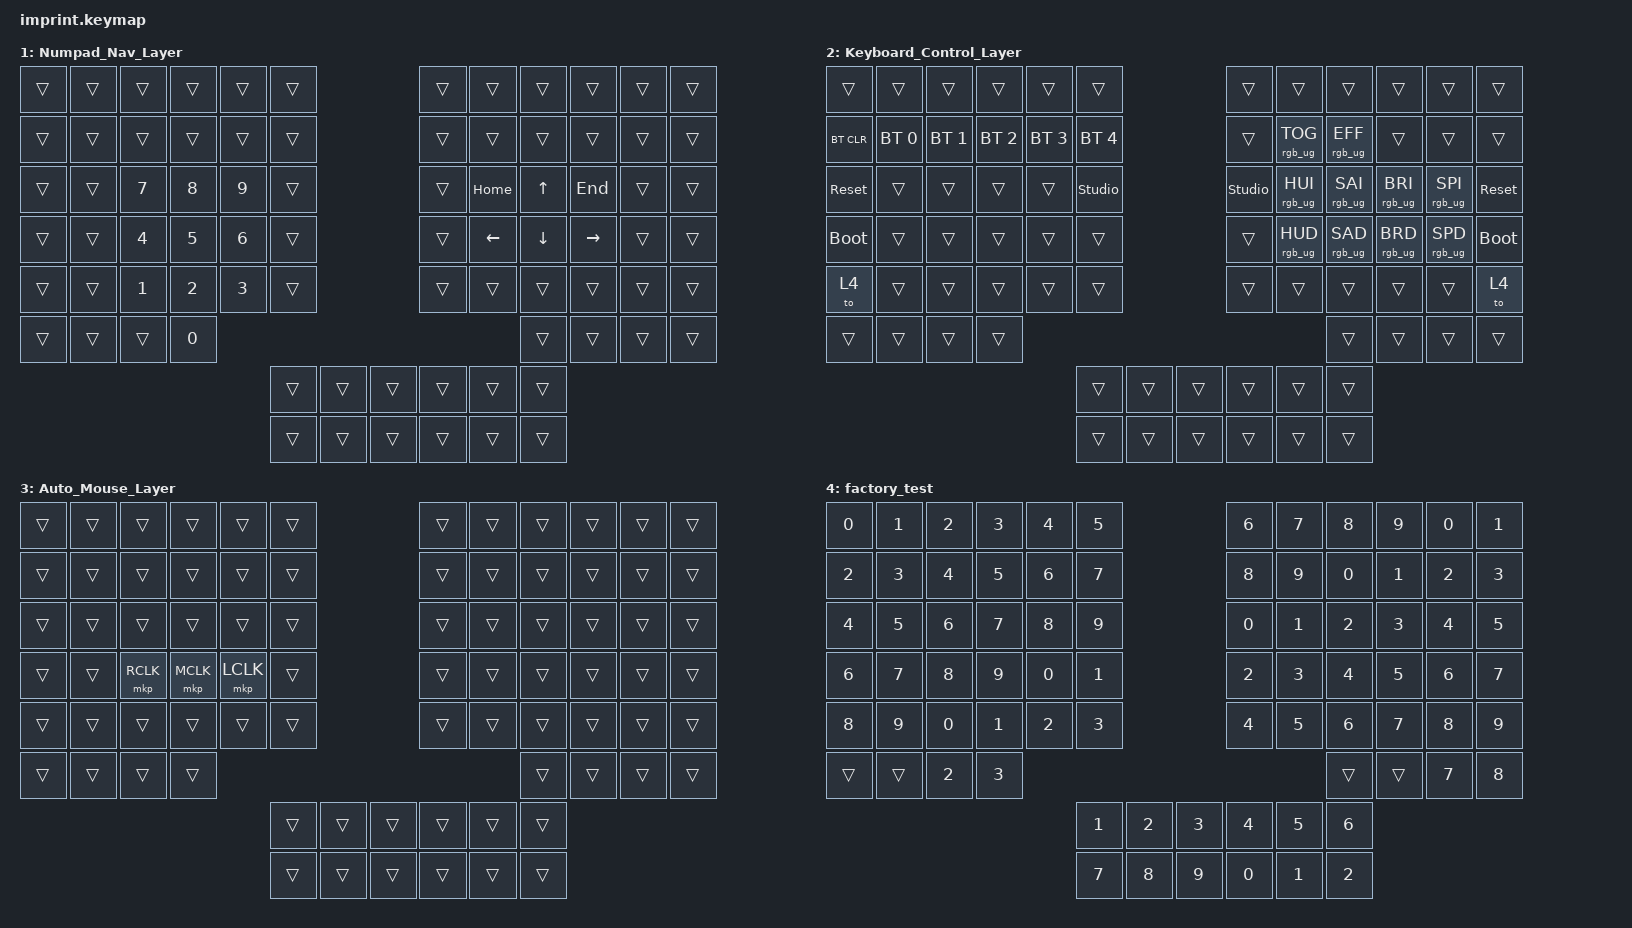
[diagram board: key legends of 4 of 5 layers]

#include <input/processors.dtsi>
#include <dt-bindings/zmk/input_transform.h>
#include <behaviors.dtsi>
#include <dt-bindings/zmk/bt.h>
#include <dt-bindings/zmk/keys.h>
#include <dt-bindings/zmk/pointing.h>
#include <dt-bindings/zmk/rgb.h>

/ {
    chosen { zmk,matrix-transform = &imprint_function_row_full_bottom_row; };
    macros {
        double_r_bkt: double_r_bkt {
            compatible = "zmk,behavior-macro";
            #binding-cells = <0>;
            bindings = <&kp LBKT &kp LBKT>;
            label = "DOUBLE_R_BKT";
        };

        double_l_bkt: double_l_bkt {
            compatible = "zmk,behavior-macro";
            #binding-cells = <0>;
            bindings = <&kp RBKT &kp RBKT>;

            label = "DOUBLE_L_BKT";
        };

        right_bfr: right_bfr {
            compatible = "zmk,behavior-macro";
            #binding-cells = <0>;
            bindings = <&kp RBKT &kp B>;
            label = "RIGHT_BFR";
        };

        left_bfr: left_bfr {
            compatible = "zmk,behavior-macro";
            #binding-cells = <0>;
            bindings = <&kp LBKT &kp B>;
            label = "LEFT_BFR";
        };

        vim_scroll_down: vim_scroll_down {
            compatible = "zmk,behavior-macro";
            #binding-cells = <0>;
            bindings = <&kp LCTRL &kp D>;
            label = "SCROLL_DOWN_VIM";
        };

        vim_scroll_up: vim_scroll_up {
            compatible = "zmk,behavior-macro";
            #binding-cells = <0>;
            bindings = <&kp LCTRL &kp U>;
            label = "SCROLL_UP_VIM";
        };

    };

    keymap {
        compatible = "zmk,keymap";

        default_layer {
            bindings = <
&kp CAPS            &kp F1       &kp F2           &kp F3          &kp F4         &kp F5                            &kp F6         &kp F7        &kp F8          &kp F9          &kp F10         &kp F11
&kp EQUAL           &kp N1       &kp N2           &kp N3          &kp N4         &kp N5                            &kp N6         &kp N7        &kp N8          &kp N9          &kp N0          &kp MINUS
&kp TAB             &kp Q        &kp W            &kp E           &kp R          &kp T                             &kp Y          &kp U         &kp I           &kp O           &kp P           &kp BSLH
&kp ESC             &mt LSHFT A  &mt LCTRL S      &mt LALT D      &mt LGUI F     &kp G                             &kp H          &mt RGUI J    &mt RALT K      &mt RCTRL L     &mt RSHFT SEMI  &kp SQT
&mt LSHFT LC(LEFT)  &kp Z        &kp X            &kp C           &kp V          &kp B                             &kp N          &kp M         &kp COMMA       &kp DOT         &kp FSLH        &mt RSHFT LC(RIGHT)
&kp LC(LEFT)        &lt 2 LC(SPACE)  &mt LCTRL GRAVE  &mt LALT LEFT  &mt LGUI RIGHT                                                &mt RGUI UP    &mt RALT DOWN &mt RALT LBKT   &mt RCTRL RBKT  &kp LC(RIGHT)
                                                                  &vim_scroll_down  &kp LC(D)        &double_l_bkt    &double_r_bkt  &kp LC(U)  &vim_scroll_up
                                                                  &mt LGUI BSPC  &lt 1 LC(SLASH)  &left_bfr        &right_bfr     &lt 2 RETURN  &mt RGUI SPACE
            >;
        };

        Numpad_Nav_Layer {
            bindings = <
 &trans  &trans  &trans  &trans  &trans  &trans                                     &trans  &trans   &trans   &trans    &trans  &trans
 &trans  &trans  &trans  &trans  &trans  &trans                                     &trans  &trans   &trans   &trans    &trans  &trans
 &trans  &trans  &kp N7  &kp N8  &kp N9  &trans                                     &trans  &kp HOME &kp UP   &kp END   &trans  &trans
 &trans  &trans  &kp N4  &kp N5  &kp N6  &trans                                     &trans  &kp LEFT &kp DOWN &kp RIGHT &trans  &trans
 &trans  &trans  &kp N1  &kp N2  &kp N3  &trans                                     &trans  &trans   &trans   &trans    &trans  &trans
 &trans  &trans  &trans  &kp N0                                                                      &trans   &trans    &trans  &trans
                                      &trans  &trans &trans       &trans  &trans &trans
                                      &trans  &trans &trans       &trans  &trans &trans
            >;
        };

        Keyboard_Control_Layer {
            bindings = <
 &trans      &trans  &trans  &trans  &trans  &trans                                     &trans         &trans           &trans          &trans          &trans          &trans
 &bt BT_CLR  &bt BT_SEL 0 &bt BT_SEL 1 &bt BT_SEL 2 &bt BT_SEL 3 &bt BT_SEL 4           &trans         &rgb_ug RGB_TOG  &rgb_ug RGB_EFF &trans          &trans          &trans
 &sys_reset      &trans  &trans  &trans  &trans  &studio_unlock                             &studio_unlock &rgb_ug RGB_HUI  &rgb_ug RGB_SAI &rgb_ug RGB_BRI &rgb_ug RGB_SPI &sys_reset
 &bootloader &trans  &trans  &trans  &trans  &trans                                     &trans         &rgb_ug RGB_HUD  &rgb_ug RGB_SAD &rgb_ug RGB_BRD &rgb_ug RGB_SPD &bootloader
 &to 4      &trans  &trans  &trans  &trans  &trans                                     &trans         &trans           &trans          &trans          &trans          &to 4
 &trans  &trans  &trans  &trans                                                                                         &trans          &trans       &trans  &trans
                                         &trans  &trans &trans        &trans &trans &trans
                                         &trans  &trans &trans        &trans &trans &trans
            >;
        };

        Auto_Mouse_Layer {
            bindings = <
 &trans  &trans  &trans  &trans  &trans  &trans                                     &trans  &trans  &trans  &trans  &trans  &trans
 &trans  &trans  &trans  &trans  &trans  &trans                                     &trans  &trans  &trans  &trans  &trans  &trans
 &trans  &trans  &trans  &trans  &trans  &trans                                     &trans  &trans  &trans  &trans  &trans  &trans
 &trans  &trans  &mkp RCLK  &mkp MCLK  &mkp LCLK  &trans                            &trans  &trans  &trans  &trans  &trans  &trans
 &trans  &trans  &trans  &trans  &trans  &trans                                     &trans  &trans  &trans  &trans  &trans  &trans
 &trans  &trans &trans  &trans                                                              &trans  &trans &trans  &trans
                                         &trans  &trans &trans        &trans &trans &trans
                                         &trans  &trans &trans        &trans &trans &trans
            >;
        };

        factory_test {
            bindings = <
&kp N0  &kp N1  &kp N2  &kp N3  &kp N4  &kp N5            &kp N6  &kp N7  &kp N8  &kp N9  &kp N0  &kp N1
&kp N2  &kp N3  &kp N4  &kp N5  &kp N6  &kp N7            &kp N8  &kp N9  &kp N0  &kp N1  &kp N2  &kp N3
&kp N4  &kp N5  &kp N6  &kp N7  &kp N8  &kp N9            &kp N0  &kp N1  &kp N2  &kp N3  &kp N4  &kp N5
&kp N6  &kp N7  &kp N8  &kp N9  &kp N0  &kp N1            &kp N2  &kp N3  &kp N4  &kp N5  &kp N6  &kp N7
&kp N8  &kp N9  &kp N0  &kp N1  &kp N2  &kp N3            &kp N4  &kp N5  &kp N6  &kp N7  &kp N8  &kp N9
&trans  &trans  &kp N2  &kp N3                                    &trans  &trans &kp N7  &kp N8
                                &kp N1  &kp N2  &kp N3    &kp N4  &kp N5  &kp N6
                                &kp N7  &kp N8  &kp N9    &kp N0  &kp N1  &kp N2
            >;
        };
    };
};

//right hand trackball configuration

&trackball_peripheral_listener {
    input-processors =
        // this gets it to the default installation orientation,
        // <&zip_xy_transform INPUT_TRANSFORM_XY_SWAP>,

    // activate layer 3 within 500ms of the trackball moving
        <&zip_temp_layer 3 500>;
};

//left hand trackball configuration

&trackball_central_listener {
    input-processors =
        // this gets it to the default installation orientation,
        // <&zip_xy_transform INPUT_TRANSFORM_XY_SWAP>,
        // multiply sensitivity by 1, divide by 3 (make it slower for scrolling),
        <&zip_xy_scaler 1 4>,
        // make this trackball output scrolling events by default instead of cursor movement,
        <&zip_xy_to_scroll_mapper>,
        // invert vertical scrolling so that the view moves in the same direction as the top of the trackball.,
        <&zip_scroll_transform INPUT_TRANSFORM_Y_INVERT>;
};

&mt {
    tapping-term-ms = <200>;
    quick-tap-ms = <300>;
    flavor = "tap-preferred";
};

